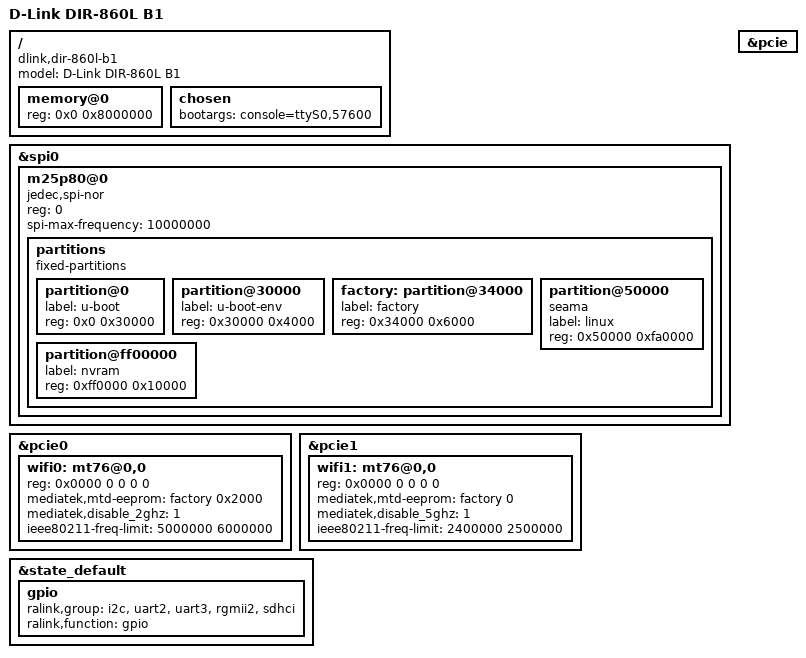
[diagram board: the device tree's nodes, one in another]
/dts-v1/;

#include "mt7621.dtsi"

#include <dt-bindings/gpio/gpio.h>
#include <dt-bindings/input/input.h>

/ {
	compatible = "dlink,dir-860l-b1", "mediatek,mt7621-soc";
	model = "D-Link DIR-860L B1";

	memory@0 {
		device_type = "memory";
		reg = <0x0 0x8000000>;
	};

	chosen {
		bootargs = "console=ttyS0,57600";
	};
};

&spi0 {
	status = "okay";

	m25p80@0 {
		compatible = "jedec,spi-nor";
		reg = <0>;
		spi-max-frequency = <10000000>;


		partitions {
			compatible = "fixed-partitions";
			#address-cells = <1>;
			#size-cells = <1>;
				partition@0 {
					label = "u-boot";
					reg = <0x0 0x30000>;
				};

				partition@30000 {
					label = "u-boot-env";
					reg = <0x30000 0x4000>;
				};

				factory: partition@34000 {
					label = "factory";
					reg = <0x34000 0x6000>;
				};

				partition@50000 {
					compatible = "seama";
					label = "linux";
					reg = <0x50000 0xfa0000>;
				};

				partition@ff00000 {
					label = "nvram";
					reg = <0xff0000 0x10000>;
				};
		};

	};
};

&pcie {
	status = "okay";
};

&pcie0 {
	wifi0: mt76@0,0 {
		reg = <0x0000 0 0 0 0>;
		mediatek,mtd-eeprom = <&factory 0x2000>;
		mediatek,disable_2ghz = <1>;
		ieee80211-freq-limit = <5000000 6000000>;
	};
};

&pcie1 {
	wifi1: mt76@0,0 {
		reg = <0x0000 0 0 0 0>;
		mediatek,mtd-eeprom = <&factory 0>;
		mediatek,disable_5ghz = <1>;
		ieee80211-freq-limit = <2400000 2500000>;
	};
};

&state_default {
	gpio {
		ralink,group = "i2c", "uart2", "uart3", "rgmii2", "sdhci";
		ralink,function = "gpio";
	};
};
